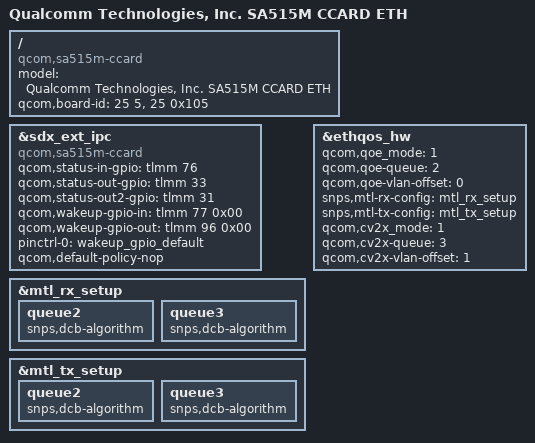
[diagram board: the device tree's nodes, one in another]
/dts-v1/;

#include "sa515m.dtsi"
#include "sa515m-ccard.dtsi"

/ {
	model = "Qualcomm Technologies, Inc. SA515M CCARD ETH";
	compatible = "qcom,sa515m-ccard",
			"qcom,sa515m", "qcom,ccard";
	qcom,board-id = <25 5>, <25 0x105>;
};

&sdx_ext_ipc {
	compatible = "qcom,sa515m-ccard";
	qcom,status-in-gpio = <&tlmm 76 0x00>;
	qcom,status-out-gpio = <&tlmm 33 0x00>;
	qcom,status-out2-gpio = <&tlmm 31 0x00>;
	qcom,wakeup-gpio-in = <&tlmm 77 0x00>;
	qcom,wakeup-gpio-out = <&tlmm 96 0x00>;
	pinctrl-names = "default";
	pinctrl-0 = <&wakeup_gpio_default>;
	qcom,default-policy-nop;
	status = "okay";
};

&mtl_rx_setup {
	queue2 {
		snps,dcb-algorithm;
	};

	queue3 {
		snps,dcb-algorithm;
	};
};

&mtl_tx_setup {
	queue2 {
		snps,dcb-algorithm;
	};

	queue3 {
		snps,dcb-algorithm;
	};
};

&ethqos_hw {
	qcom,qoe_mode = <1>;
	qcom,qoe-queue = <2>;
	qcom,qoe-vlan-offset = <0>;
	snps,mtl-rx-config = <&mtl_rx_setup>;
	snps,mtl-tx-config = <&mtl_tx_setup>;
	qcom,cv2x_mode = <1>;
	qcom,cv2x-queue = <3>;
	qcom,cv2x-vlan-offset = <1>;
};

